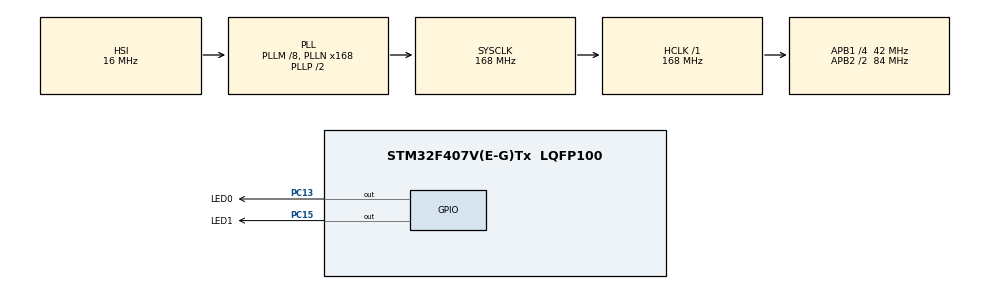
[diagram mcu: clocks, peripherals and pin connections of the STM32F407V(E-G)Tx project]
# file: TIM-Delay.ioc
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Mcu.Family=STM32F4
Mcu.Name=STM32F407V(E-G)Tx
Mcu.Package=LQFP100
NVIC.PriorityGroup=NVIC_PRIORITYGROUP_4
NVIC.TIM6_DAC_IRQn=true\:0\:0\:false\:false\:true\:true\:true
PC13-ANTI_TAMP.GPIO_Label=LED0
PC13-ANTI_TAMP.Signal=GPIO_Output
PC15-OSC32_OUT.GPIO_Label=LED1
PC15-OSC32_OUT.Signal=GPIO_Output
ProjectManager.HeapSize=0x200
ProjectManager.StackSize=0x400
ProjectManager.TargetToolchain=MDK-ARM V5.27
RCC.48MHZClocksFreq_Value=84000000
RCC.AHBFreq_Value=168000000
RCC.APB1CLKDivider=RCC_HCLK_DIV4
RCC.APB1Freq_Value=42000000
RCC.APB1TimFreq_Value=84000000
RCC.APB2CLKDivider=RCC_HCLK_DIV2
RCC.APB2Freq_Value=84000000
RCC.APB2TimFreq_Value=168000000
RCC.CortexFreq_Value=168000000
RCC.HCLKFreq_Value=168000000
RCC.HSE_VALUE=25000000
RCC.HSI_VALUE=16000000
RCC.LSE_VALUE=32768
RCC.PLLM=8
RCC.PLLN=168
RCC.SYSCLKFreq_VALUE=168000000
RCC.SYSCLKSource=RCC_SYSCLKSOURCE_PLLCLK
RCC.VCOOutputFreq_Value=336000000
TIM6.Period=10000-1
TIM6.Prescaler=8400-1
VP_TIM6_VS_ClockSourceINT.Mode=Enable_Timer
VP_TIM7_VS_ClockSourceINT.Mode=Enable_Timer
board=custom

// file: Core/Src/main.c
/* USER CODE BEGIN Header */
/**
  ******************************************************************************
  * @file           : main.c
  * @brief          : Main program body
  ******************************************************************************
  * @attention
  *
  * <h2><center>&copy; Copyright (c) 2023 STMicroelectronics.
  * All rights reserved.</center></h2>
  *
  * This software component is licensed by ST under BSD 3-Clause license,
  * the "License"; You may not use this file except in compliance with the
  * License. You may obtain a copy of the License at:
  *                        opensource.org/licenses/BSD-3-Clause
  *
  ******************************************************************************
  */
/* USER CODE END Header */
#include "main.h"
#include "tim.h"
#include "gpio.h"

/* USER CODE BEGIN PM */
#define DELAY_TIM             htim7
#define DELAY_CLK             84000000

#define DELAY_US_PRESCALER    ((DELAY_CLK / 1000000) - 1)
#define DELAY_US_ARR_M        1

#if DELAY_CLK >= 65535000
  #define DELAY_MS_PRESCALER  ((DELAY_CLK / 10000UL) - 1)
  #define DELAY_MS_ARR_M      10
#else
  #define DELAY_MS_PRESCALER  ((DELAY_CLK / 1000UL) - 1)
  #define DELAY_MS_ARR_M      1
#endif

/* USER CODE END PM */

void SystemClock_Config(void);
/* USER CODE BEGIN PFP */
void Delay_us(uint32_t us);
void Delay_ms(uint32_t us);
/* USER CODE END PFP */

int main(void)
{

  /* MCU Configuration--------------------------------------------------------*/

  /* Reset of all peripherals, Initializes the Flash interface and the Systick. */
  HAL_Init();

  /* Configure the system clock */
  SystemClock_Config();

  /* Initialize all configured peripherals */
  MX_GPIO_Init();
  MX_TIM6_Init();
  MX_TIM7_Init();
  /* USER CODE BEGIN 2 */
  HAL_TIM_Base_Start_IT(&htim6);
  /* USER CODE END 2 */

  /* Infinite loop */
  /* USER CODE BEGIN WHILE */

  while (1)
  {
    Delay_ms(1000);
    HAL_GPIO_TogglePin(LED1_GPIO_Port, LED1_Pin);
    /* USER CODE END WHILE */

  }
}

void SystemClock_Config(void)
{
  RCC_OscInitTypeDef RCC_OscInitStruct = {0};
  RCC_ClkInitTypeDef RCC_ClkInitStruct = {0};

  /** Configure the main internal regulator output voltage
  */
  __HAL_RCC_PWR_CLK_ENABLE();
  __HAL_PWR_VOLTAGESCALING_CONFIG(PWR_REGULATOR_VOLTAGE_SCALE1);
  /** Initializes the RCC Oscillators according to the specified parameters
  * in the RCC_OscInitTypeDef structure.
  */
  RCC_OscInitStruct.OscillatorType = RCC_OSCILLATORTYPE_HSI;
  RCC_OscInitStruct.HSIState = RCC_HSI_ON;
  RCC_OscInitStruct.HSICalibrationValue = RCC_HSICALIBRATION_DEFAULT;
  RCC_OscInitStruct.PLL.PLLState = RCC_PLL_ON;
  RCC_OscInitStruct.PLL.PLLSource = RCC_PLLSOURCE_HSI;
  RCC_OscInitStruct.PLL.PLLM = 8;
  RCC_OscInitStruct.PLL.PLLN = 168;
  RCC_OscInitStruct.PLL.PLLP = RCC_PLLP_DIV2;
  RCC_OscInitStruct.PLL.PLLQ = 4;
  if (HAL_RCC_OscConfig(&RCC_OscInitStruct) != HAL_OK)
  {
    Error_Handler();
  }
  /** Initializes the CPU, AHB and APB buses clocks
  */
  RCC_ClkInitStruct.ClockType = RCC_CLOCKTYPE_HCLK|RCC_CLOCKTYPE_SYSCLK
                              |RCC_CLOCKTYPE_PCLK1|RCC_CLOCKTYPE_PCLK2;
  RCC_ClkInitStruct.SYSCLKSource = RCC_SYSCLKSOURCE_PLLCLK;
  RCC_ClkInitStruct.AHBCLKDivider = RCC_SYSCLK_DIV1;
  RCC_ClkInitStruct.APB1CLKDivider = RCC_HCLK_DIV4;
  RCC_ClkInitStruct.APB2CLKDivider = RCC_HCLK_DIV2;

  if (HAL_RCC_ClockConfig(&RCC_ClkInitStruct, FLASH_LATENCY_5) != HAL_OK)
  {
    Error_Handler();
  }
}

/* USER CODE BEGIN 4 */
void Delay_us(uint32_t us) {
  __HAL_TIM_SET_PRESCALER(&DELAY_TIM, DELAY_US_PRESCALER);
  __HAL_TIM_SET_AUTORELOAD(&DELAY_TIM, us * DELAY_US_ARR_M - 1);

  __HAL_TIM_CLEAR_FLAG(&DELAY_TIM, TIM_FLAG_UPDATE);
  HAL_TIM_Base_Start(&DELAY_TIM);
  while (__HAL_TIM_GET_FLAG(&DELAY_TIM, TIM_FLAG_UPDATE) == RESET) {
    __NOP();
  }
  HAL_TIM_Base_Stop(&DELAY_TIM);
}

void Delay_ms(uint32_t ms) {
  __HAL_TIM_SET_PRESCALER(&DELAY_TIM, DELAY_MS_PRESCALER);
  __HAL_TIM_SET_AUTORELOAD(&DELAY_TIM, ms * DELAY_MS_ARR_M - 1);

  __HAL_TIM_CLEAR_FLAG(&DELAY_TIM, TIM_FLAG_UPDATE);
  HAL_TIM_Base_Start(&DELAY_TIM);
  while (__HAL_TIM_GET_FLAG(&DELAY_TIM, TIM_FLAG_UPDATE) == RESET) {
    __NOP();
  }
  HAL_TIM_Base_Stop(&DELAY_TIM);
}

void HAL_TIM_PeriodElapsedCallback(TIM_HandleTypeDef* htim) {
  HAL_GPIO_TogglePin(LED0_GPIO_Port, LED0_Pin);
}
/* USER CODE END 4 */

void Error_Handler(void)
{
  __disable_irq();
  while (1)
  {
  }
}

/************************ (C) COPYRIGHT STMicroelectronics *****END OF FILE****/
